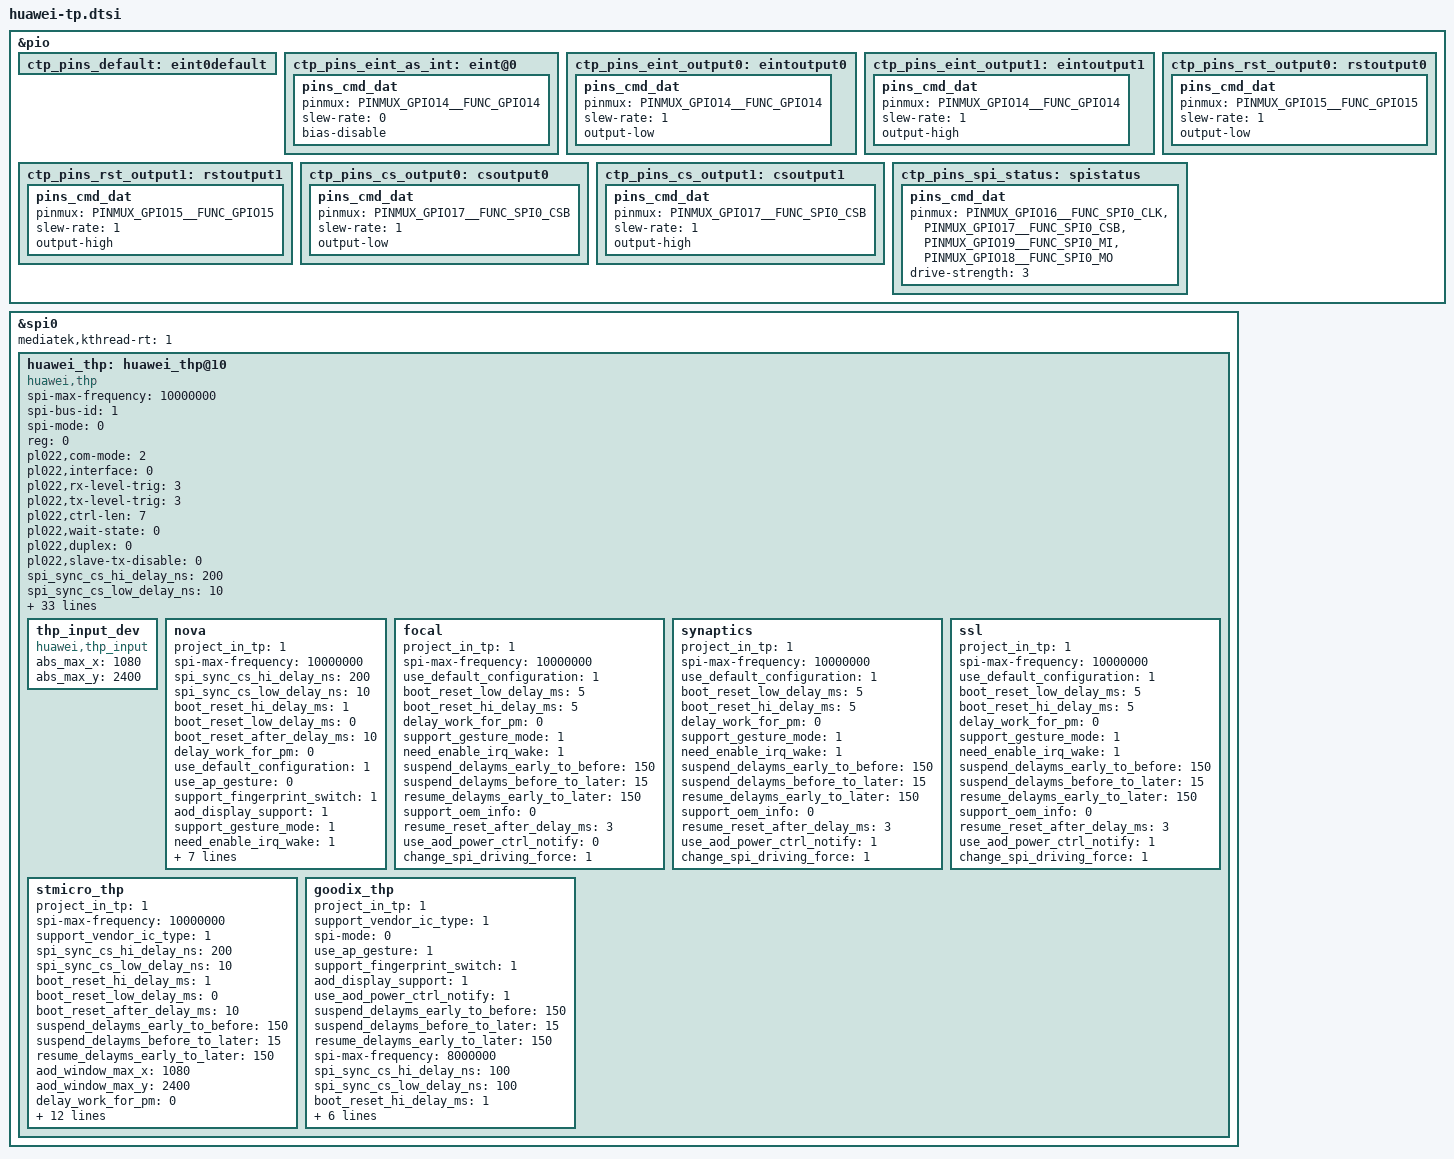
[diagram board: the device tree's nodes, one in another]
&pio {
	ctp_pins_default: eint0default {
	};
	ctp_pins_eint_as_int: eint@0 {
		pins_cmd_dat {
			pinmux = <PINMUX_GPIO14__FUNC_GPIO14>;
			slew-rate = <0>;
			bias-disable;
		};
	};
	ctp_pins_eint_output0: eintoutput0 {
		pins_cmd_dat {
			pinmux = <PINMUX_GPIO14__FUNC_GPIO14>;
			slew-rate = <1>;
			output-low;
		};
	};
	ctp_pins_eint_output1: eintoutput1 {
		pins_cmd_dat {
			pinmux = <PINMUX_GPIO14__FUNC_GPIO14>;
			slew-rate = <1>;
			output-high;
		};
	};
	ctp_pins_rst_output0: rstoutput0 {
		pins_cmd_dat {
			pinmux = <PINMUX_GPIO15__FUNC_GPIO15>;
			slew-rate = <1>;
			output-low;
		};
	};
	ctp_pins_rst_output1: rstoutput1 {
		pins_cmd_dat {
			pinmux = <PINMUX_GPIO15__FUNC_GPIO15>;
			slew-rate = <1>;
			output-high;
		};
	};

	ctp_pins_cs_output0: csoutput0 {
		pins_cmd_dat {
			pinmux = <PINMUX_GPIO17__FUNC_SPI0_CSB>;
			slew-rate = <1>;
			output-low;
		};
	};
	ctp_pins_cs_output1: csoutput1 {
		pins_cmd_dat {
			pinmux = <PINMUX_GPIO17__FUNC_SPI0_CSB>;
			slew-rate = <1>;
			output-high;
		};
	};
	ctp_pins_spi_status: spistatus   {
		pins_cmd_dat {
			pinmux = <PINMUX_GPIO16__FUNC_SPI0_CLK>,
				 <PINMUX_GPIO17__FUNC_SPI0_CSB>,
				 <PINMUX_GPIO19__FUNC_SPI0_MI>,
				 <PINMUX_GPIO18__FUNC_SPI0_MO>;
			drive-strength = <3>;
		};
	};
};

&spi0 {
	status = "ok";
	mediatek,kthread-rt = <1>;
	huawei_thp: huawei_thp@10 {
		compatible = "huawei,thp";
		/* SPI Config */
		spi-max-frequency = <10000000>;
		spi-bus-id = <1>;
		spi-mode = <0>;
		reg = <0>;
		pl022,com-mode = <2>;
		pl022,interface = <0>;
		pl022,rx-level-trig = <3>;
		pl022,tx-level-trig = <3>;
		pl022,ctrl-len = <7>;
		pl022,wait-state = <0>;
		pl022,duplex = <0>;
		pl022,slave-tx-disable = <0>;
		spi_sync_cs_hi_delay_ns  = <200>;
		spi_sync_cs_low_delay_ns = <10>;
		/* Power Config */
		boot_reset_hi_delay_ms = <1>;
		boot_reset_low_delay_ms = <0>;
		boot_reset_after_delay_ms = <0>;
		resume_reset_after_delay_ms = <3>;
		suspend_reset_after_delay_ms = <0>;
		use_mdelay = <1>;
		/* GPIO Config */
		irq_flag = <0x00004002>;
		debounce = <6 0>;
		interrupt-parent = <&pio>;
		interrupts = <14 2 0 0>;
		thp-vcc-type = <1>; /* 0-unsued 1-ldo 2-gpio */
		thp-vcc-supply = <&mt_pmic_vtp_ldo_reg>;
		thp-vcc-value = <3100000>;
		//thp-iovdd-type = <2>;
		//thp-iovdd-gpio = <&pio 137 0>;
		//thp-iovdd-value = <1800000>;
		/* PinCtrl Config */
		support_pinctrl = <1>;
		pinctrl-names = "default", "idle", "state_eint_as_int", "state_rst_output0",
			"state_rst_output1", "state_cs_output0", "state_cs_output1", "state_spi_status";
		pinctrl-0 = <&ctp_pins_rst_output1 &ctp_pins_cs_output1>;
		pinctrl-1 = <&ctp_pins_rst_output0 &ctp_pins_cs_output0>;
		pinctrl-2 = <&ctp_pins_eint_as_int>;
		pinctrl-3 = <&ctp_pins_rst_output0>;
		pinctrl-4 = <&ctp_pins_rst_output1>;
		pinctrl-5 = <&ctp_pins_cs_output0>;
		pinctrl-6 = <&ctp_pins_cs_output1>;
		pinctrl-7 = <&ctp_pins_spi_status>;

		/* Feature Config */
		pt_station_test = <1>;
		proximity_support = <0>;
		hide_product_info_en = <0>;
		support_gesture_mode = <1>;
		need_enable_irq_wake = <1>;
		change_spi_driving_force = <1>;
		need_notify_to_roi_algo = <1>;
		fast_booting_solution = <1>;
		supported_charger = <1>;
		/* Input Config */
		thp_input_dev {
			compatible = "huawei,thp_input";
			abs_max_x = <1080>;
			abs_max_y = <2400>;
		};
		nova {
			project_in_tp = <1>;
			spi-max-frequency = <10000000>;
			spi_sync_cs_hi_delay_ns = <200>;
			spi_sync_cs_low_delay_ns = <10>;
			boot_reset_hi_delay_ms = <1>;
			boot_reset_low_delay_ms = <0>;
			boot_reset_after_delay_ms = <10>;
			delay_work_for_pm = <0>;
			use_default_configuration = <1>;
			use_ap_gesture = <0>;
			support_fingerprint_switch = <1>;
			aod_display_support = <1>;
			support_gesture_mode = <1>;
			need_enable_irq_wake = <1>;
			suspend_delayms_early_to_before = <150>;
			suspend_delayms_before_to_later = <15>;
			resume_delayms_early_to_later = <150>;
			support_oem_info = <0>;
			resume_reset_after_delay_ms = <3>;
			use_aod_power_ctrl_notify = <0>;
			change_spi_driving_force = <1>;
		};
		focal {
			project_in_tp = <1>;
			spi-max-frequency = <10000000>;
			use_default_configuration = <1>;
			boot_reset_low_delay_ms = <5>;
			boot_reset_hi_delay_ms = <5>;
			delay_work_for_pm = <0>;
			support_gesture_mode = <1>;
			need_enable_irq_wake = <1>;
			suspend_delayms_early_to_before = <150>;
			suspend_delayms_before_to_later = <15>;
			resume_delayms_early_to_later = <150>;
			support_oem_info = <0>;
			resume_reset_after_delay_ms = <3>;
			use_aod_power_ctrl_notify = <0>;
			change_spi_driving_force = <1>;
		};
		synaptics {
			project_in_tp = <1>;
			spi-max-frequency = <10000000>;
			use_default_configuration = <1>;
			boot_reset_low_delay_ms = <5>;
			boot_reset_hi_delay_ms = <5>;
			delay_work_for_pm = <0>;
			support_gesture_mode = <1>;
			need_enable_irq_wake = <1>;
			suspend_delayms_early_to_before = <150>;
			suspend_delayms_before_to_later = <15>;
			resume_delayms_early_to_later = <150>;
			support_oem_info = <0>;
			resume_reset_after_delay_ms = <3>;
			use_aod_power_ctrl_notify = <1>;
			change_spi_driving_force = <1>;
		};
		ssl {
			project_in_tp = <1>;
			spi-max-frequency = <10000000>;
			use_default_configuration = <1>;
			boot_reset_low_delay_ms = <5>;
			boot_reset_hi_delay_ms = <5>;
			delay_work_for_pm = <0>;
			support_gesture_mode = <1>;
			need_enable_irq_wake = <1>;
			suspend_delayms_early_to_before = <150>;
			suspend_delayms_before_to_later = <15>;
			resume_delayms_early_to_later = <150>;
			support_oem_info = <0>;
			resume_reset_after_delay_ms = <3>;
			use_aod_power_ctrl_notify = <1>;
			change_spi_driving_force = <1>;
		};
		stmicro_thp {
			project_in_tp = <1>;
			spi-max-frequency = <10000000>;
			support_vendor_ic_type = <1>;
			spi_sync_cs_hi_delay_ns = <200>;
			spi_sync_cs_low_delay_ns = <10>;
			boot_reset_hi_delay_ms = <1>;
			boot_reset_low_delay_ms = <0>;
			boot_reset_after_delay_ms = <10>;
			suspend_delayms_early_to_before = <150>;
			suspend_delayms_before_to_later = <15>;
			resume_delayms_early_to_later = <150>;
			aod_window_max_x = <1080>;
			aod_window_max_y = <2400>;
			delay_work_for_pm = <0>;
			st_force_node_default = <16>;
			st_sense_node_default = <34>;
			use_ap_gesture = <1>;
			support_fingerprint_switch = <1>;
			aod_display_support = <1>;
			use_aod_power_ctrl_notify = <1>;
			support_gesture_mode = <1>;
			need_enable_irq_wake = <1>;
			support_oem_info = <0>;
			resume_reset_after_delay_ms = <3>;
			need_resume_reset = <0>;
			change_spi_driving_force = <1>;
		};
		goodix_thp {
                        project_in_tp = <1>;
                        support_vendor_ic_type = <1>;
                        spi-mode = <0>;
			use_ap_gesture = <1>;
                        support_fingerprint_switch = <1>;
			aod_display_support = <1>;
			use_aod_power_ctrl_notify = <1>;
			suspend_delayms_early_to_before = <150>;
			suspend_delayms_before_to_later = <15>;
			resume_delayms_early_to_later = <150>;
                        spi-max-frequency = <8000000>;
                        spi_sync_cs_hi_delay_ns = <100>;
                        spi_sync_cs_low_delay_ns = <100>;
                        boot_reset_hi_delay_ms = <1>;
                        boot_reset_low_delay_ms = <1>;
                        boot_reset_after_delay_ms = <100>;
                        support_gesture_mode = <1>;
                        need_enable_irq_wake = <1>;
                        project_id_dummy = "B185970900";
                        change_spi_driving_force = <1>;
                };

	};
};
